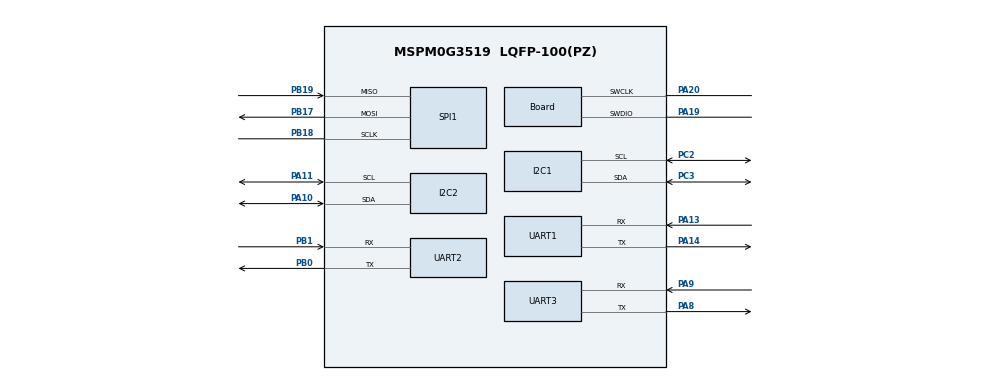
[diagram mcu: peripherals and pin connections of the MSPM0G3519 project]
/**
 * These arguments were used when this file was generated. They will be automatically applied on subsequent loads
 * via the GUI or CLI. Run CLI with '--help' for additional information on how to override these arguments.
 * @cliArgs --device "MSPM0G351X" --part "Default" --package "LQFP-100(PZ)" --product "mspm0_sdk@2.10.00.04"
 * @v2CliArgs --device "MSPM0G3519" --package "LQFP-100(PZ)" --product "mspm0_sdk@2.10.00.04"
 * @versions {"tool":"1.26.2+4477"}
 */

/**
 * Import the modules used in this configuration.
 */
const ADC12  = scripting.addModule("/ti/driverlib/ADC12", {}, false);
const ADC121 = ADC12.addInstance();
const GPIO   = scripting.addModule("/ti/driverlib/GPIO", {}, false);
const GPIO1  = GPIO.addInstance();
const GPIO2  = GPIO.addInstance();
const GPIO3  = GPIO.addInstance();
const GPIO4  = GPIO.addInstance();
const GPIO5  = GPIO.addInstance();
const GPIO6  = GPIO.addInstance();
const GPIO7  = GPIO.addInstance();
const GPIO8  = GPIO.addInstance();
const GPIO9  = GPIO.addInstance();
const GPIO10 = GPIO.addInstance();
const I2C    = scripting.addModule("/ti/driverlib/I2C", {}, false);
const I2C1   = I2C.addInstance();
const I2C2   = I2C.addInstance();
const SPI    = scripting.addModule("/ti/driverlib/SPI", {}, false);
const SPI1   = SPI.addInstance();
const SYSCTL = scripting.addModule("/ti/driverlib/SYSCTL");
const UART   = scripting.addModule("/ti/driverlib/UART", {}, false);
const UART1  = UART.addInstance();
const UART2  = UART.addInstance();
const UART3  = UART.addInstance();

/**
 * Write custom configuration values to the imported modules.
 */
const divider6       = system.clockTree["PLL_CLK2X_DIV"];
divider6.divideValue = 4;

const divider7       = system.clockTree["PLL_PDIV"];
divider7.divideValue = 2;

const divider9       = system.clockTree["UDIV"];
divider9.divideValue = 2;

const multiplier2         = system.clockTree["PLL_QDIV"];
multiplier2.multiplyValue = 10;

const mux8       = system.clockTree["HSCLKMUX"];
mux8.inputSelect = "HSCLKMUX_SYSPLL2X";

ADC121.$name                             = "GRAYSCALE_ADC";
ADC121.sampClkSrc                        = "DL_ADC12_CLOCK_ULPCLK";
ADC121.sampClkDiv                        = "DL_ADC12_CLOCK_DIVIDE_8";
ADC121.sampleTime0                       = "125 us";
ADC121.adcMem0avgen                      = true;
ADC121.hwNumerator                       = "DL_ADC12_HW_AVG_NUM_ACC_4";
ADC121.hwDenominator                     = "DL_ADC12_HW_AVG_DEN_DIV_BY_4";
ADC121.enabledInterrupts                 = ["DL_ADC12_INTERRUPT_MEM0_RESULT_LOADED"];
ADC121.interruptPriority                 = "3";
ADC121.powerDownMode                     = "DL_ADC12_POWER_DOWN_MODE_MANUAL";
ADC121.sampCnt                           = 1;
ADC121.peripheral.$assign                = "ADC1";
ADC121.peripheral.adcPin0.$assign        = "PA15";
ADC121.adcPin0Config.$name               = "ti_driverlib_gpio_GPIOPinGeneric14";
ADC121.adcPin0Config.hideOutputInversion = scripting.forceWrite(false);

const Board                       = scripting.addModule("/ti/driverlib/Board", {}, false);
Board.peripheral.$assign          = "DEBUGSS";
Board.peripheral.swclkPin.$assign = "PA20";
Board.peripheral.swdioPin.$assign = "PA19";

GPIO1.$name                          = "GPIO_LED_A";
GPIO1.port                           = "PORTA";
GPIO1.portSegment                    = "Upper";
GPIO1.associatedPins.create(2);
GPIO1.associatedPins[0].$name        = "LED1";
GPIO1.associatedPins[0].initialValue = "SET";
GPIO1.associatedPins[0].assignedPin  = "27";
GPIO1.associatedPins[1].$name        = "LED2";
GPIO1.associatedPins[1].initialValue = "SET";
GPIO1.associatedPins[1].assignedPin  = "26";

GPIO2.$name                         = "GPIO_BUZZER";
GPIO2.port                          = "PORTC";
GPIO2.portSegment                   = "Upper";
GPIO2.associatedPins[0].$name       = "BUZZER";
GPIO2.associatedPins[0].assignedPin = "16";

GPIO3.$name                              = "GPIO_BUTTON_C";
GPIO3.port                               = "PORTC";
GPIO3.portSegment                        = "Lower";
GPIO3.associatedPins[0].$name            = "BUTTON1";
GPIO3.associatedPins[0].direction        = "INPUT";
GPIO3.associatedPins[0].internalResistor = "PULL_UP";
GPIO3.associatedPins[0].assignedPin      = "9";

GPIO4.$name                              = "GPIO_BUTTON_B";
GPIO4.port                               = "PORTB";
GPIO4.portSegment                        = "Upper";
GPIO4.associatedPins.create(2);
GPIO4.associatedPins[0].$name            = "BUTTON2";
GPIO4.associatedPins[0].direction        = "INPUT";
GPIO4.associatedPins[0].internalResistor = "PULL_UP";
GPIO4.associatedPins[0].assignedPin      = "20";
GPIO4.associatedPins[1].$name            = "BUTTON3";
GPIO4.associatedPins[1].direction        = "INPUT";
GPIO4.associatedPins[1].internalResistor = "PULL_UP";
GPIO4.associatedPins[1].assignedPin      = "23";

GPIO5.$name                          = "GPIO_IMU_C";
GPIO5.port                           = "PORTC";
GPIO5.portSegment                    = "Lower";
GPIO5.associatedPins.create(3);
GPIO5.associatedPins[0].$name        = "ICM45686_INT1";
GPIO5.associatedPins[0].direction    = "INPUT";
GPIO5.associatedPins[0].assignedPin  = "6";
GPIO5.associatedPins[1].$name        = "ICM45686_CS";
GPIO5.associatedPins[1].initialValue = "SET";
GPIO5.associatedPins[1].assignedPin  = "7";
GPIO5.associatedPins[2].$name        = "LIS3MDL_CS";
GPIO5.associatedPins[2].initialValue = "SET";
GPIO5.associatedPins[2].assignedPin  = "8";

GPIO6.$name                         = "GPIO_IMU_A";
GPIO6.port                          = "PORTA";
GPIO6.portSegment                   = "Upper";
GPIO6.associatedPins.create(2);
GPIO6.associatedPins[0].$name       = "LIS3MDL_DRDY";
GPIO6.associatedPins[0].direction   = "INPUT";
GPIO6.associatedPins[0].assignedPin = "22";
GPIO6.associatedPins[1].$name       = "ICM45686_INT2_FSYNC";
GPIO6.associatedPins[1].direction   = "INPUT";
GPIO6.associatedPins[1].assignedPin = "31";

GPIO7.$name                          = "GPIO_LED_B";
GPIO7.port                           = "PORTB";
GPIO7.portSegment                    = "Upper";
GPIO7.associatedPins[0].$name        = "LED3";
GPIO7.associatedPins[0].initialValue = "SET";
GPIO7.associatedPins[0].assignedPin  = "27";

GPIO8.$name                              = "GPIO_GY931_I2C";
GPIO8.port                               = "PORTA";
GPIO8.portSegment                        = "Upper";
GPIO8.associatedPins.create(2);
GPIO8.associatedPins[0].$name            = "GY931_SCL";
GPIO8.associatedPins[0].direction        = "INPUT";
GPIO8.associatedPins[0].internalResistor = "PULL_UP";
GPIO8.associatedPins[0].assignedPin      = "29";
GPIO8.associatedPins[1].$name            = "GY931_SDA";
GPIO8.associatedPins[1].direction        = "INPUT";
GPIO8.associatedPins[1].internalResistor = "PULL_UP";
GPIO8.associatedPins[1].assignedPin      = "30";

GPIO9.$name                         = "GPIO_GRAY_C";
GPIO9.port                          = "PORTC";
GPIO9.portSegment                   = "Upper";
GPIO9.associatedPins.create(2);
GPIO9.associatedPins[0].$name       = "GRAY_SEL0";
GPIO9.associatedPins[0].assignedPin = "21";
GPIO9.associatedPins[1].$name       = "GRAY_SEL1";
GPIO9.associatedPins[1].assignedPin = "20";

GPIO10.$name                         = "GPIO_GRAY_A";
GPIO10.port                          = "PORTA";
GPIO10.portSegment                   = "Upper";
GPIO10.associatedPins[0].$name       = "GRAY_SEL2";
GPIO10.associatedPins[0].assignedPin = "16";

I2C1.basicEnableController             = true;
I2C1.basicControllerBusSpeed           = 400000;
I2C1.$name                             = "SENSOR_I2C";
I2C1.advAnalogGlitchFilter             = "DISABLED";
I2C1.peripheral.$assign                = "I2C2";
I2C1.peripheral.sdaPin.$assign         = "PC3";
I2C1.peripheral.sclPin.$assign         = "PC2";
I2C1.sdaPinConfig.$name                = "ti_driverlib_gpio_GPIOPinGeneric6";
I2C1.sdaPinConfig.hideOutputInversion  = scripting.forceWrite(false);
I2C1.sdaPinConfig.onlyInternalResistor = scripting.forceWrite(false);
I2C1.sdaPinConfig.passedPeripheralType = scripting.forceWrite("Digital");
I2C1.sclPinConfig.$name                = "ti_driverlib_gpio_GPIOPinGeneric7";
I2C1.sclPinConfig.hideOutputInversion  = scripting.forceWrite(false);
I2C1.sclPinConfig.onlyInternalResistor = scripting.forceWrite(false);
I2C1.sclPinConfig.passedPeripheralType = scripting.forceWrite("Digital");

I2C2.basicEnableController             = true;
I2C2.basicControllerBusSpeed           = 400000;
I2C2.$name                             = "MOTOR_I2C";
I2C2.advAnalogGlitchFilter             = "50";
I2C2.peripheral.$assign                = "I2C1";
I2C2.peripheral.sdaPin.$assign         = "PA10";
I2C2.peripheral.sclPin.$assign         = "PA11";
I2C2.sdaPinConfig.$name                = "ti_driverlib_gpio_GPIOPinGeneric8";
I2C2.sdaPinConfig.hideOutputInversion  = scripting.forceWrite(false);
I2C2.sdaPinConfig.onlyInternalResistor = scripting.forceWrite(false);
I2C2.sdaPinConfig.passedPeripheralType = scripting.forceWrite("Digital");
I2C2.sclPinConfig.$name                = "ti_driverlib_gpio_GPIOPinGeneric9";
I2C2.sclPinConfig.hideOutputInversion  = scripting.forceWrite(false);
I2C2.sclPinConfig.onlyInternalResistor = scripting.forceWrite(false);
I2C2.sclPinConfig.passedPeripheralType = scripting.forceWrite("Digital");

SPI1.$name                              = "IMU_SPI";
SPI1.targetBitRate                      = 1000000;
SPI1.frameFormat                        = "MOTO3";
SPI1.polarity                           = "1";
SPI1.phase                              = "1";
SPI1.sclkPinConfig.$name                = "ti_driverlib_gpio_GPIOPinGeneric10";
SPI1.sclkPinConfig.direction            = scripting.forceWrite("OUTPUT");
SPI1.sclkPinConfig.onlyInternalResistor = scripting.forceWrite(false);
SPI1.sclkPinConfig.passedPeripheralType = scripting.forceWrite("Digital");
SPI1.mosiPinConfig.$name                = "ti_driverlib_gpio_GPIOPinGeneric11";
SPI1.mosiPinConfig.direction            = scripting.forceWrite("OUTPUT");
SPI1.mosiPinConfig.hideOutputInversion  = scripting.forceWrite(false);
SPI1.mosiPinConfig.onlyInternalResistor = scripting.forceWrite(false);
SPI1.mosiPinConfig.passedPeripheralType = scripting.forceWrite("Digital");
SPI1.misoPinConfig.$name                = "ti_driverlib_gpio_GPIOPinGeneric12";
SPI1.misoPinConfig.onlyInternalResistor = scripting.forceWrite(false);
SPI1.misoPinConfig.passedPeripheralType = scripting.forceWrite("Digital");
SPI1.peripheral.sclkPin.$assign         = "PB18";
SPI1.peripheral.mosiPin.$assign         = "PB17";
SPI1.peripheral.misoPin.$assign         = "PB19";

SYSCTL.forceDefaultClkConfig = true;
SYSCTL.clockTreeEn           = true;
SYSCTL.validateClkStatus     = true;

UART1.$name                            = "DEBUG_UART";
UART1.rxFifoThreshold                  = "DL_UART_RX_FIFO_LEVEL_ONE_ENTRY";
UART1.targetBaudRate                   = 115200;
UART1.enableFIFO                       = true;
UART1.txFifoThreshold                  = "DL_UART_TX_FIFO_LEVEL_3_4_EMPTY";
UART1.enableDMARX                      = false;
UART1.enableDMATX                      = false;
UART1.enabledInterrupts                = ["RX"];
UART1.peripheral.$assign               = "UART3";
UART1.peripheral.rxPin.$assign         = "PA13";
UART1.peripheral.txPin.$assign         = "PA14";
UART1.txPinConfig.$name                = "ti_driverlib_gpio_GPIOPinGeneric0";
UART1.txPinConfig.direction            = scripting.forceWrite("OUTPUT");
UART1.txPinConfig.hideOutputInversion  = scripting.forceWrite(false);
UART1.txPinConfig.onlyInternalResistor = scripting.forceWrite(false);
UART1.txPinConfig.passedPeripheralType = scripting.forceWrite("Digital");
UART1.rxPinConfig.$name                = "ti_driverlib_gpio_GPIOPinGeneric1";
UART1.rxPinConfig.hideOutputInversion  = scripting.forceWrite(false);
UART1.rxPinConfig.onlyInternalResistor = scripting.forceWrite(false);
UART1.rxPinConfig.passedPeripheralType = scripting.forceWrite("Digital");

UART2.$name                            = "LORA_UART";
UART2.rxFifoThreshold                  = "DL_UART_RX_FIFO_LEVEL_ONE_ENTRY";
UART2.targetBaudRate                   = 115200;
UART2.enableFIFO                       = true;
UART2.txFifoThreshold                  = "DL_UART_TX_FIFO_LEVEL_3_4_EMPTY";
UART2.enableDMARX                      = false;
UART2.enableDMATX                      = false;
UART2.enabledInterrupts                = ["RX"];
UART2.peripheral.$assign               = "UART0";
UART2.peripheral.rxPin.$assign         = "PB1";
UART2.peripheral.txPin.$assign         = "PB0";
UART2.txPinConfig.$name                = "ti_driverlib_gpio_GPIOPinGeneric2";
UART2.txPinConfig.direction            = scripting.forceWrite("OUTPUT");
UART2.txPinConfig.hideOutputInversion  = scripting.forceWrite(false);
UART2.txPinConfig.onlyInternalResistor = scripting.forceWrite(false);
UART2.txPinConfig.passedPeripheralType = scripting.forceWrite("Digital");
UART2.rxPinConfig.$name                = "ti_driverlib_gpio_GPIOPinGeneric3";
UART2.rxPinConfig.hideOutputInversion  = scripting.forceWrite(false);
UART2.rxPinConfig.onlyInternalResistor = scripting.forceWrite(false);
UART2.rxPinConfig.passedPeripheralType = scripting.forceWrite("Digital");

UART3.$name                            = "MOTOR_UART";
UART3.rxFifoThreshold                  = "DL_UART_RX_FIFO_LEVEL_ONE_ENTRY";
UART3.targetBaudRate                   = 115200;
UART3.enableFIFO                       = true;
UART3.txFifoThreshold                  = "DL_UART_TX_FIFO_LEVEL_3_4_EMPTY";
UART3.enableDMARX                      = false;
UART3.enableDMATX                      = false;
UART3.enabledInterrupts                = ["RX"];
UART3.peripheral.$assign               = "UART1";
UART3.peripheral.rxPin.$assign         = "PA9";
UART3.peripheral.txPin.$assign         = "PA8";
UART3.txPinConfig.$name                = "ti_driverlib_gpio_GPIOPinGeneric4";
UART3.txPinConfig.direction            = scripting.forceWrite("OUTPUT");
UART3.txPinConfig.hideOutputInversion  = scripting.forceWrite(false);
UART3.txPinConfig.onlyInternalResistor = scripting.forceWrite(false);
UART3.txPinConfig.passedPeripheralType = scripting.forceWrite("Digital");
UART3.rxPinConfig.$name                = "ti_driverlib_gpio_GPIOPinGeneric5";
UART3.rxPinConfig.hideOutputInversion  = scripting.forceWrite(false);
UART3.rxPinConfig.onlyInternalResistor = scripting.forceWrite(false);
UART3.rxPinConfig.passedPeripheralType = scripting.forceWrite("Digital");

const ProjectConfig              = scripting.addModule("/ti/project_config/ProjectConfig", {}, false);
ProjectConfig.migrationCondition = true;

/**
 * Pinmux solution for unlocked pins/peripherals. This ensures that minor changes to the automatic solver in a future
 * version of the tool will not impact the pinmux you originally saw.  These lines can be completely deleted in order to
 * re-solve from scratch.
 */
GPIO1.associatedPins[0].pin.$suggestSolution  = "PA27";
GPIO1.associatedPins[1].pin.$suggestSolution  = "PA26";
GPIO2.associatedPins[0].pin.$suggestSolution  = "PC16";
GPIO3.associatedPins[0].pin.$suggestSolution  = "PC9";
GPIO4.associatedPins[0].pin.$suggestSolution  = "PB20";
GPIO4.associatedPins[1].pin.$suggestSolution  = "PB23";
GPIO5.associatedPins[0].pin.$suggestSolution  = "PC6";
GPIO5.associatedPins[1].pin.$suggestSolution  = "PC7";
GPIO5.associatedPins[2].pin.$suggestSolution  = "PC8";
GPIO6.associatedPins[0].pin.$suggestSolution  = "PA22";
GPIO6.associatedPins[1].pin.$suggestSolution  = "PA31";
GPIO7.associatedPins[0].pin.$suggestSolution  = "PB27";
GPIO8.associatedPins[0].pin.$suggestSolution  = "PA29";
GPIO8.associatedPins[1].pin.$suggestSolution  = "PA30";
GPIO9.associatedPins[0].pin.$suggestSolution  = "PC21";
GPIO9.associatedPins[1].pin.$suggestSolution  = "PC20";
GPIO10.associatedPins[0].pin.$suggestSolution = "PA16";
SPI1.peripheral.$suggestSolution              = "SPI0";
